# ATSAMG54G19 register map
Vendor: Atmel; Series: SAMG54; File version: 0
CPU: CM4 r0p1, selectable endian, MPU, FPU, 4 interrupt priority bits
Registers are 32-bit, read-write, reset 0x0 unless marked. A register's access mark holds for its fields unless they carry their own. Offsets are from the block's base; [hi:lo] are bit positions.

## TWI1 — Two-wire Interface 1
Base 0x4001C000; register names take the prefix TWI1_
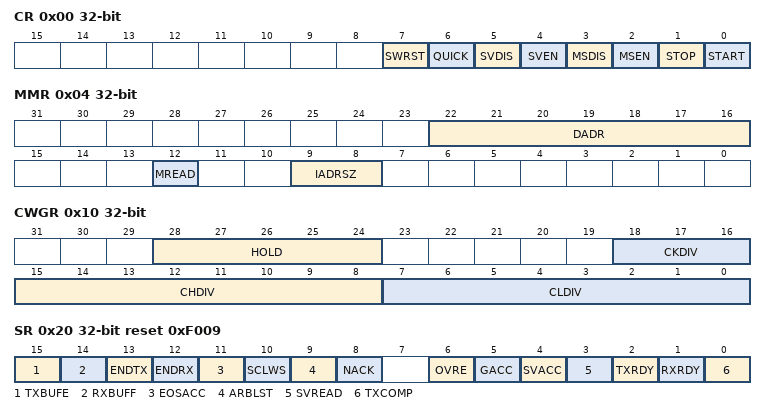
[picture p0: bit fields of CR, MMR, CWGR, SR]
0x00 CR wo reset not defined — Control Register
  [7] SWRST — Software Reset
  [6] QUICK — SMBus Quick Command
  [5] SVDIS — TWI Slave Mode Disabled
  [4] SVEN — TWI Slave Mode Enabled
  [3] MSDIS — TWI Master Mode Disabled
  [2] MSEN — TWI Master Mode Enabled
  [1] STOP — Send a STOP Condition
  [0] START — Send a START Condition
0x04 MMR — Master Mode Register
  [22:16] DADR — Device Address
  [12] MREAD — Master Read Direction
  [9:8] IADRSZ — Internal Device Address Size
    0=NONE (No internal device address); 1=1_BYTE (One-byte internal device address); 2=2_BYTE (Two-byte internal device address); 3=3_BYTE (Three-byte internal device address)
0x08 SMR — Slave Mode Register
  [22:16] SADR — Slave Address
0x0C IADR — Internal Address Register
  [23:0] IADR — Internal Address
0x10 CWGR — Clock Waveform Generator Register
  [28:24] HOLD — TWD Hold Time versus TWCK falling
  [18:16] CKDIV — Clock Divider
  [15:8] CHDIV — Clock High Divider
  [7:0] CLDIV — Clock Low Divider
0x20 SR ro reset 0xF009 — Status Register
  [15] TXBUFE — TX Buffer Empty (cleared by writing TWI_TCR or TWI_TNCR)
  [14] RXBUFF — RX Buffer Full (cleared by writing TWI_RCR or TWI_RNCR)
  [13] ENDTX — End of TX buffer (cleared by writing TWI_TCR or TWI_TNCR)
  [12] ENDRX — End of RX buffer (cleared by writing TWI_RCR or TWI_RNCR)
  [11] EOSACC — End Of Slave Access (cleared on read)
  [10] SCLWS — Clock Wait State
  [9] ARBLST — Arbitration Lost (cleared on read)
  [8] NACK — Not Acknowledged (cleared on read)
  [6] OVRE — Overrun Error (cleared on read)
  [5] GACC — General Call Access (cleared on read)
  [4] SVACC — Slave Access
  [3] SVREAD — Slave Read
  [2] TXRDY — Transmit Holding Register Ready (cleared by writing TWI_THR)
  [1] RXRDY — Receive Holding Register Ready (cleared by reading TWI_RHR)
  [0] TXCOMP — Transmission Completed (cleared by writing TWI_THR)
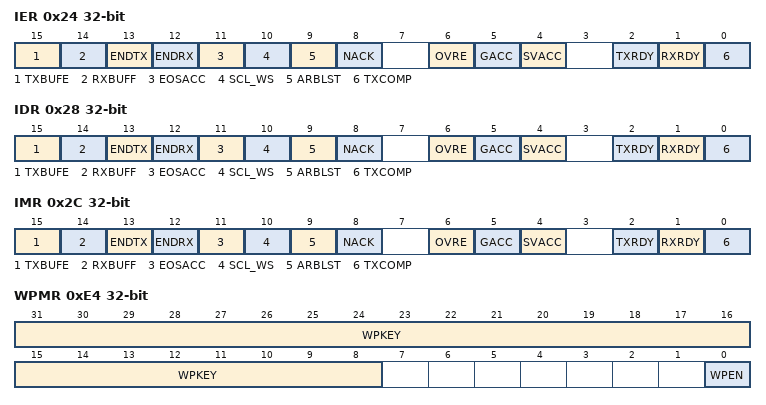
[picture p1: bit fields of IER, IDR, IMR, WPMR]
0x24 IER wo reset not defined — Interrupt Enable Register
  [15] TXBUFE — Transmit Buffer Empty Interrupt Enable
  [14] RXBUFF — Receive Buffer Full Interrupt Enable
  [13] ENDTX — End of Transmit Buffer Interrupt Enable
  [12] ENDRX — End of Receive Buffer Interrupt Enable
  [11] EOSACC — End Of Slave Access Interrupt Enable
  [10] SCL_WS — Clock Wait State Interrupt Enable
  [9] ARBLST — Arbitration Lost Interrupt Enable
  [8] NACK — Not Acknowledge Interrupt Enable
  [6] OVRE — Overrun Error Interrupt Enable
  [5] GACC — General Call Access Interrupt Enable
  [4] SVACC — Slave Access Interrupt Enable
  [2] TXRDY — Transmit Holding Register Ready Interrupt Enable
  [1] RXRDY — Receive Holding Register Ready Interrupt Enable
  [0] TXCOMP — Transmission Completed Interrupt Enable
0x28 IDR wo reset not defined — Interrupt Disable Register
  [15] TXBUFE — Transmit Buffer Empty Interrupt Disable
  [14] RXBUFF — Receive Buffer Full Interrupt Disable
  [13] ENDTX — End of Transmit Buffer Interrupt Disable
  [12] ENDRX — End of Receive Buffer Interrupt Disable
  [11] EOSACC — End Of Slave Access Interrupt Disable
  [10] SCL_WS — Clock Wait State Interrupt Disable
  [9] ARBLST — Arbitration Lost Interrupt Disable
  [8] NACK — Not Acknowledge Interrupt Disable
  [6] OVRE — Overrun Error Interrupt Disable
  [5] GACC — General Call Access Interrupt Disable
  [4] SVACC — Slave Access Interrupt Disable
  [2] TXRDY — Transmit Holding Register Ready Interrupt Disable
  [1] RXRDY — Receive Holding Register Ready Interrupt Disable
  [0] TXCOMP — Transmission Completed Interrupt Disable
0x2C IMR ro — Interrupt Mask Register
  [15] TXBUFE — Transmit Buffer Empty Interrupt Mask
  [14] RXBUFF — Receive Buffer Full Interrupt Mask
  [13] ENDTX — End of Transmit Buffer Interrupt Mask
  [12] ENDRX — End of Receive Buffer Interrupt Mask
  [11] EOSACC — End Of Slave Access Interrupt Mask
  [10] SCL_WS — Clock Wait State Interrupt Mask
  [9] ARBLST — Arbitration Lost Interrupt Mask
  [8] NACK — Not Acknowledge Interrupt Mask
  [6] OVRE — Overrun Error Interrupt Mask
  [5] GACC — General Call Access Interrupt Mask
  [4] SVACC — Slave Access Interrupt Mask
  [2] TXRDY — Transmit Holding Register Ready Interrupt Mask
  [1] RXRDY — Receive Holding Register Ready Interrupt Mask
  [0] TXCOMP — Transmission Completed Interrupt Mask
0x30 RHR ro — Receive Holding Register
  [7:0] RXDATA — Master or Slave Receive Holding Data
0x34 THR wo reset not defined — Transmit Holding Register
  [7:0] TXDATA — Master or Slave Transmit Holding Data
0xE4 WPMR — Write Protection Mode Register
  [31:8] WPKEY — Write Protection Key
    0x545749=PASSWD (Writing any other value in this field aborts the write operation of the WPEN bit.Always reads as 0)
  [0] WPEN — Write Protection Enable
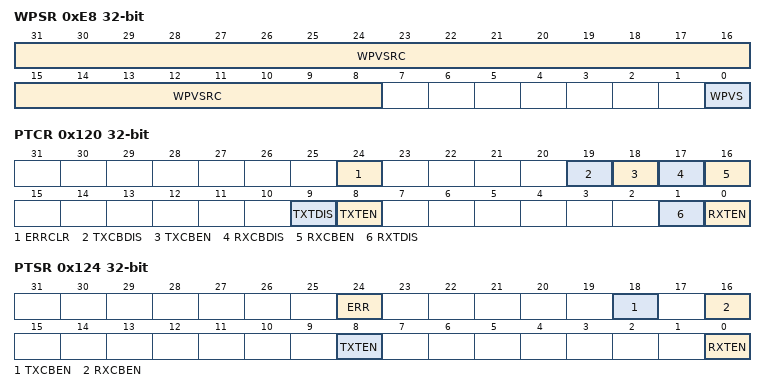
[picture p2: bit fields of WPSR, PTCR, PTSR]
0xE8 WPSR ro — Write Protection Status Register
  [31:8] WPVSRC — Write Protection Violation Source
  [0] WPVS — Write Protection Violation Status
0x100 RPR — Receive Pointer Register
  [31:0] RXPTR
0x104 RCR — Receive Counter Register
  [15:0] RXCTR
0x108 TPR — Transmit Pointer Register
  [31:0] TXPTR — Transmit Counter Register
0x10C TCR — Transmit Counter Register
  [15:0] TXCTR
0x110 RNPR — Receive Next Pointer Register
  [31:0] RXNPTR — Receive Next Pointer
0x114 RNCR — Receive Next Counter Register
  [15:0] RXNCTR — Receive Next Counter
0x118 TNPR — Transmit Next Pointer Register
  [31:0] TXNPTR — Transmit Next Pointer
0x11C TNCR — Transmit Next Counter Register
  [15:0] TXNCTR — Transmit Counter Next
0x120 PTCR wo reset not defined — Transfer Control Register
  [24] ERRCLR — Transfer Bus Error Clear
  [19] TXCBDIS — Transmitter Circular Buffer Disable
  [18] TXCBEN — Transmitter Circular Buffer Enable
  [17] RXCBDIS — Receiver Circular Buffer Disable
  [16] RXCBEN — Receiver Circular Buffer Enable
  [9] TXTDIS — Transmitter Transfer Disable
  [8] TXTEN — Transmitter Transfer Enable
  [1] RXTDIS — Receiver Transfer Disable
  [0] RXTEN — Receiver Transfer Enable
0x124 PTSR ro — Transfer Status Register
  [24] ERR — Transfer Bus Error
  [18] TXCBEN — Transmitter Circular Buffer Enable
  [16] RXCBEN — Receiver Circular Buffer Enable
  [8] TXTEN — Transmitter Transfer Enable
  [0] RXTEN — Receiver Transfer Enable

## TWI2 — Two-wire Interface 2
Base 0x40040000; register names take the prefix TWI2_
Registers as TWI1.

## Notices in the file
SAM Software Package License
Copyright (c) %copyright_year%, Atmel Corporation
All rights reserved.
Redistribution and use in source and binary forms, with or without
modification, are permitted provided that the following condition is met:
- Redistributions of source code must retain the above copyright notice,
this list of conditions and the disclaimer below.
Atmel's name may not be used to endorse or promote products derived from
this software without specific prior written permission.
DISCLAIMER:  THIS SOFTWARE IS PROVIDED BY ATMEL "AS IS" AND ANY EXPRESS OR
IMPLIED WARRANTIES, INCLUDING, BUT NOT LIMITED TO, THE IMPLIED WARRANTIES OF
MERCHANTABILITY, FITNESS FOR A PARTICULAR PURPOSE AND NON-INFRINGEMENT ARE
DISCLAIMED. IN NO EVENT SHALL ATMEL BE LIABLE FOR ANY DIRECT, INDIRECT,
INCIDENTAL, SPECIAL, EXEMPLARY, OR CONSEQUENTIAL DAMAGES (INCLUDING, BUT NOT
LIMITED TO, PROCUREMENT OF SUBSTITUTE GOODS OR SERVICES; LOSS OF USE, DATA,
OR PROFITS; OR BUSINESS INTERRUPTION) HOWEVER CAUSED AND ON ANY THEORY OF
LIABILITY, WHETHER IN CONTRACT, STRICT LIABILITY, OR TORT (INCLUDING
NEGLIGENCE OR OTHERWISE) ARISING IN ANY WAY OUT OF THE USE OF THIS SOFTWARE,
EVEN IF ADVISED OF THE POSSIBILITY OF SUCH DAMAGE.
